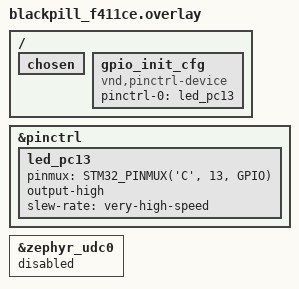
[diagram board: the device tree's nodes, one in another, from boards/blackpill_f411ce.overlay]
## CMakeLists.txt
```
# SPDX-License-Identifier: Apache-2.0

cmake_minimum_required(VERSION 3.20.0)
find_package(Zephyr REQUIRED HINTS $ENV{ZEPHYR_BASE})
project(blinky)

target_sources(app PRIVATE 
    src/main.c 
    # src/cdc_uart.c
    src/service.c
)

set(ELF_FILE ${PROJECT_BINARY_DIR}/zephyr/zephyr.elf)

add_custom_target(dap-flash
    COMMAND openocd -f interface/cmsis-dap.cfg -f target/stm32f4x.cfg -c "program ${ELF_FILE} verify reset exit"
    DEPENDS ${ELF_FILE}
    COMMENT "正在透過 dap-link 燒錄 ${ELF_FILE} ..."
    USES_TERMINAL
)
```

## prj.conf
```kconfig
CONFIG_GPIO=y

# CONFIG_USB_DEVICE_STACK=y
# CONFIG_USB_DEVICE_VID=0x2FE9
# CONFIG_USB_DEVICE_PID=0x0100
# CONFIG_USB_DEVICE_MANUFACTURER="Zephyr"
# CONFIG_USB_DEVICE_PRODUCT="Zephyr Tracing"

# CONFIG_USB_CDC_ACM=y
# CONFIG_USB_CDC_ACM_RINGBUF_SIZE=4096
# CONFIG_UART_LINE_CTRL=y

CONFIG_CONSOLE=y
CONFIG_LOG=y
# CONFIG_SHELL=y


# CONFIG_DEBUG=y
CONFIG_USE_SEGGER_RTT=y
CONFIG_SEGGER_RTT_MAX_NUM_UP_BUFFERS=3
CONFIG_SEGGER_RTT_BUFFER_SIZE_UP=8192

# 1. 啟用 Tracing 與 CTF 核心
CONFIG_TRACING=y
CONFIG_TRACING_CTF=y
CONFIG_TRACING_CTF_TIMESTAMP=y

# 2. 啟用非同步緩衝與 Host 控制指令處理 (關鍵)
CONFIG_TRACING_ASYNC=y
CONFIG_TRACING_BUFFER_SIZE=8192
CONFIG_TRACING_HANDLE_HOST_CMD=n

# 3. 啟用 USB Tracing 後端
# CONFIG_TRACING_BACKEND_UART=n
# CONFIG_TRACING_BACKEND_USB=n
# CONFIG_TRACING_BACKEND_RAM=n
CONFIG_TRACING_BACKEND_RTT=y

# 追蹤特定事件 (可視需求調整)
CONFIG_TRACING_SYSCALL=n
CONFIG_TRACING_THREAD=y
CONFIG_TRACING_WORK=n
CONFIG_TRACING_ISR=n
CONFIG_TRACING_SEMAPHORE=n
CONFIG_TRACING_MUTEX=n
CONFIG_TRACING_CONDVAR=n
CONFIG_TRACING_QUEUE=n
CONFIG_TRACING_FIFO=n
CONFIG_TRACING_LIFO=n
CONFIG_TRACING_STACK=n
CONFIG_TRACING_MESSAGE_QUEUE=n
CONFIG_TRACING_MAILBOX=n
CONFIG_TRACING_PIPE=n
CONFIG_TRACING_HEAP=n
CONFIG_TRACING_MEMORY_SLAB=n
CONFIG_TRACING_TIMER=n
CONFIG_TRACING_EVENT=n
CONFIG_TRACING_POLLING=n
CONFIG_TRACING_PM=n
```

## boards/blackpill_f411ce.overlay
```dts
#include <zephyr/dt-bindings/pinctrl/stm32-pinctrl.h>

/ {
    chosen {
        /delete-property/ zephyr,shell-uart;
    };

    gpio_init_cfg: gpio_init_cfg {
        compatible = "vnd,pinctrl-device";
        pinctrl-0 = <&led_pc13>;
        pinctrl-names = "default";
        status = "okay";
    };
};

&pinctrl {
    /omit-if-no-ref/ led_pc13: led_pc13 {
		pinmux = <STM32_PINMUX('C', 13, GPIO)>;
        // bias-disable;
        // drive-push-pull;
        output-high;
        slew-rate = "very-high-speed";
	};
};

&zephyr_udc0 {
    status = "disabled";

    // my_cdc_uart: my_cdc_uart {
    //     compatible = "zephyr,cdc-acm-uart";
    // };
};
```

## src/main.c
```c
/*
 * Copyright (c) 2016 Intel Corporation
 *
 * SPDX-License-Identifier: Apache-2.0
 */

#include <errno.h>
#include <zephyr/kernel.h>
#include <zephyr/logging/log.h>

LOG_MODULE_REGISTER(main, LOG_LEVEL_INF);

int main(void)
{
    LOG_INF("Build time : %s %s", __DATE__, __TIME__);
    LOG_INF("Hello: %s", CONFIG_BOARD_TARGET);
    return 0;
}
```

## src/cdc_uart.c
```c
#include <errno.h>
#include <limits.h>
#include <stdbool.h>
#include <stddef.h>
#include <stdint.h>

#include <zephyr/device.h>
#include <zephyr/init.h>
#include <zephyr/kernel.h>
#include <zephyr/usb/usb_device.h>

static const struct device *const usb_uart_dev =
    DEVICE_DT_GET(DT_NODELABEL(my_cdc_uart));

static int cdc_init(void) {
    int ret;

    if (!device_is_ready(usb_uart_dev)) {
        return -ENODEV;
    }

    ret = usb_enable(NULL);
    if (ret != 0) {
        return ret;
    }

    return 0;
}

SYS_INIT(cdc_init, APPLICATION, 0);
```

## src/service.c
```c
/*
 * Copyright (c) 2016 Intel Corporation
 *
 * SPDX-License-Identifier: Apache-2.0
 */

#include <stdio.h>
#include <zephyr/drivers/gpio.h>
#include <zephyr/kernel.h>
#include <zephyr/logging/log.h>

LOG_MODULE_REGISTER(blinkly, LOG_LEVEL_INF);

/* 1000 msec = 1 sec */
#define SLEEP_TIME_MS 1000

/* The devicetree node identifier for the "led0" alias. */
#define LED0_NODE DT_ALIAS(led0)

/*
 * A build error on this line means your board is unsupported.
 * See the sample documentation for information on how to fix this.
 */
static const struct gpio_dt_spec led = GPIO_DT_SPEC_GET(LED0_NODE, gpios);

static void blinkly(void) {
    int ret;
    bool led_state = true;

    if (!gpio_is_ready_dt(&led)) {
        return;
    }

    ret = gpio_pin_configure_dt(&led, GPIO_OUTPUT_ACTIVE);
    if (ret < 0) {
        return;
    }

    while (1) {
        ret = gpio_pin_toggle_dt(&led);
        if (ret < 0) {
            return;
        }

        led_state = !led_state;
        LOG_DBG("LED state: %s", led_state ? "ON" : "OFF");
        k_msleep(SLEEP_TIME_MS);
    }
}

K_THREAD_DEFINE(blink_id, 512, blinkly, NULL, NULL, NULL, 5, 0, 0);
```
